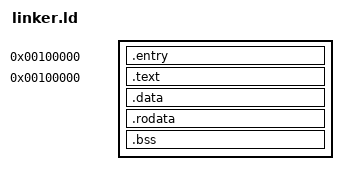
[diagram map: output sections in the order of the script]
ENTRY(start)
OUTPUT_FORMAT("binary")
phys = 0x00100000;

SECTIONS
{
    . = phys;

    .entry              : { __entry_start = .;      *(.entry)   }
    .text   0x100000            : { __text_start = .;       *(.text)    }
    .data               : { __data_start = .;       *(.data)    }
    .rodata             : { __rodata_start = .;     *(.rodata)  }
    .bss                : { __bss_start = .;        *(.bss)     }
    
    __end = .;
}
